AUTOSAR XML (schema 4-2-2)
package /Components
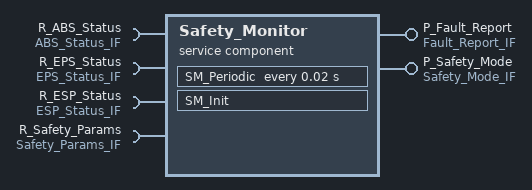
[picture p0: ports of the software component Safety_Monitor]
  service sw component type Safety_Monitor
    provide port P_Fault_Report: provided-interface=Fault_Report_IF
    provide port P_Safety_Mode: provided-interface=Safety_Mode_IF
    4 x require port:
      R_ABS_Status: required-interface=ABS_Status_IF
      R_EPS_Status: required-interface=EPS_Status_IF
      R_ESP_Status: required-interface=ESP_Status_IF
      R_Safety_Params: required-interface=Safety_Params_IF
    behavior Safety_Monitor_InternalBehavior
      init event SM_Init_Event: start-on-event=SM_Init
      timing event SM_Periodic_Event: start-on-event=SM_Periodic, period=0.02
      runnable SM_Init
        parameter access PA_Init_SafetyRuleSet: accessed-parameter=R_Safety_Params.safety_mode_ruleset
        parameter access PA_Init_FaultEscalationThreshold: accessed-parameter=R_Safety_Params.fault_escalation_threshold
      runnable SM_Periodic: minimum-start-interval=0.02
        data-receive-point-by-values:
          6 x access:
            VA_Read_ABS_Active: accessed-variable=R_ABS_Status.abs_active
            VA_Read_ABS_FaultCode: accessed-variable=R_ABS_Status.abs_fault_code
            VA_Read_EPS_Active: accessed-variable=R_EPS_Status.eps_active
            VA_Read_EPS_FaultCode: accessed-variable=R_EPS_Status.eps_fault_code
            VA_Read_ESP_Active: accessed-variable=R_ESP_Status.esp_active
            VA_Read_ESP_FaultCode: accessed-variable=R_ESP_Status.esp_fault_code
        data-send-points:
          access VA_Send_Fault_Id: accessed-variable=P_Fault_Report.fault_id
          access VA_Send_Severity: accessed-variable=P_Fault_Report.severity
          access VA_Send_Safety_Mode_State: accessed-variable=P_Safety_Mode.safety_mode_state
        parameter access PA_Periodic_FaultEscalationThreshold: accessed-parameter=R_Safety_Params.fault_escalation_threshold
